VERSION ""

NS_ :

BS_:

BU_:

BO_ 4 Brake_Heartbeat: 3 Vector__XXX
 SG_ Brake_State : 0|8@1+ (1,0) [0|0] "" Vector__XXX
 SG_ Brake_Counter : 8|16@1+ (1,0) [0|0] "" Vector__XXX

BO_ 5 Brake_Sensors: 4 Vector__XXX
 SG_ Brake_Front : 0|16@1+ (1,0) [0|0] "" Vector__XXX
 SG_ Brake_Rear : 16|16@1+ (1,0) [0|0] "" Vector__XXX

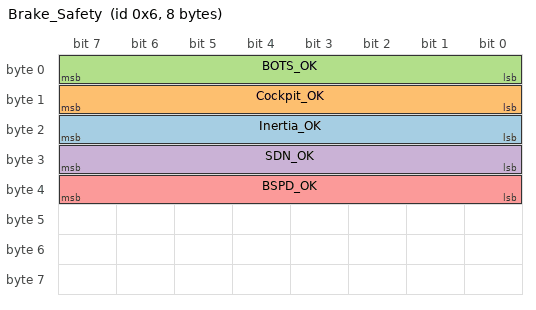
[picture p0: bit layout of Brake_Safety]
BO_ 6 Brake_Safety: 8 Vector__XXX
 SG_ Inertia_OK : 16|8@1+ (1,0) [0|0] "" Vector__XXX
 SG_ Cockpit_OK : 8|8@1+ (1,0) [0|0] "" Vector__XXX
 SG_ BOTS_OK : 0|8@1+ (1,0) [0|0] "" Vector__XXX
 SG_ SDN_OK : 24|8@1+ (1,0) [0|0] "" Vector__XXX
 SG_ BSPD_OK : 32|8@1+ (1,0) [0|0] "" Vector__XXX
